AUTOSAR XML (schema 4-0-3)
package /ComponentTypes
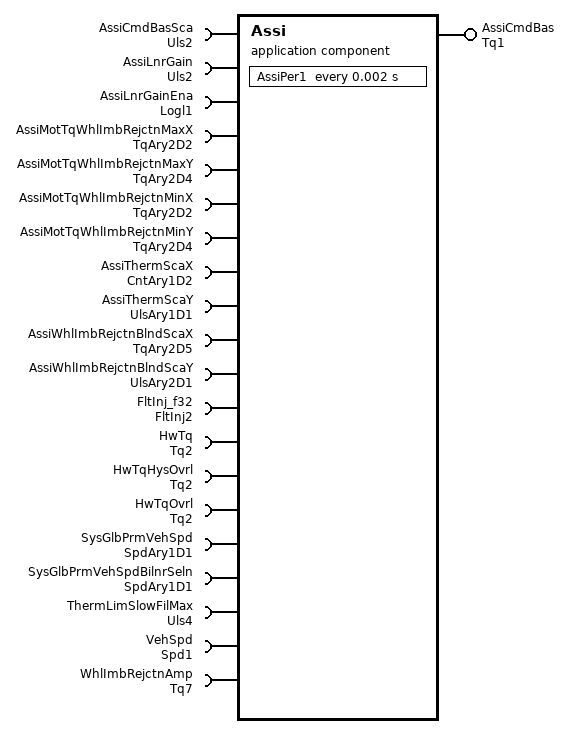
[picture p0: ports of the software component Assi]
  application sw component type Assi
    provide port AssiCmdBas: nonqueued-sender-com-spec{data-element=Val, init-value=0}, provided-interface=Tq1
    20 x require port:
      AssiCmdBasSca: nonqueued-receiver-com-spec{data-element=Val, filter=data-filter-type=ALWAYS, init-value=1}, required-interface=Uls2
      AssiLnrGain: nonqueued-receiver-com-spec{data-element=Val, filter=data-filter-type=ALWAYS, init-value=1}, required-interface=Uls2
      AssiLnrGainEna: nonqueued-receiver-com-spec{data-element=Logl, filter=data-filter-type=ALWAYS, init-value=0}, required-interface=Logl1
      AssiMotTqWhlImbRejctnMaxX: parameter-require-com-spec{init-value=[[0, 0.1015625, 0.2070313, 0.2460938, 0.2890625, 0.3359375, 0.3828125, 0.4296875, 0.4804688, 0.5234375, 0.5703125, 0.6210938, 0.6640625, 0.7109375, 0.7578125, 0.8007813, 1, 1.453125, 4.765625, 10], [0, 0.1015625, 0.3046875, 0.3945313, 0.4804688, 0.578125, 0.6679688, 0.765625, 0.859375, 0.9492188, 1.042969, 1.132813, 1.230469, 1.324219, 1.414063, 1.7, 2.2, 2.808594, 6.34375, 10], [0, 0.1992188, 0.3125, 0.4414063, 0.5664063, 0.6875, 0.8007813, 0.9296875, 1.039063, 1.160156, 1.289063, 1.40625, 1.527344, 1.648438, 1.765625, 2.1, 2.8, 3.578125, 8.65625, 10], [0, 0.1992188, 0.3125, 0.4296875, 0.5703125, 0.6757813, 0.8007813, 0.9257813, 1.039063, 1.167969, 1.289063, 1.40625, 1.53125, 1.652344, 1.765625, 1.890625, 2.5, 3.582031, 3.699219, 10], [0, 0.1992188, 0.3125, 0.4335938, 0.5585938, 0.6914063, 0.8085938, 0.9296875, 1.042969, 1.171875, 1.289063, 1.402344, 1.53125, 1.648438, 1.769531, 1.886719, 2.5, 3.2, 3.699219, 10], [0, 0.1992188, 0.3085938, 0.4335938, 0.5429688, 0.6796875, 0.8046875, 0.921875, 1.042969, 1.171875, 1.304688, 1.429688, 1.546875, 1.671875, 1.796875, 1.929688, 2.5, 3.2, 3.796875, 10], [0, 0.1992188, 0.3125, 0.4140625, 0.5546875, 0.6835938, 0.8007813, 0.9335938, 1.054688, 1.171875, 1.296875, 1.429688, 1.554688, 1.675781, 1.804688, 1.929688, 2.5, 3.2, 3.796875, 10], [0, 0.1992188, 0.390625, 0.5078125, 0.6367188, 0.7578125, 0.8945313, 1.019531, 1.136719, 1.265625, 1.386719, 1.515625, 1.640625, 1.761719, 1.886719, 2.011719, 2.5, 3.2, 3.898438, 10], [0, 0.1992188, 0.390625, 0.5078125, 0.640625, 0.765625, 0.90625, 1.015625, 1.160156, 1.277344, 1.40625, 1.546875, 1.679688, 1.804688, 1.925781, 2.058594, 2.6, 3.2, 4, 10], [0, 0.1992188, 0.390625, 0.5078125, 0.640625, 0.765625, 0.90625, 1.015625, 1.160156, 1.277344, 1.40625, 1.546875, 1.679688, 1.804688, 1.925781, 2.058594, 2.6, 3.2, 4, 10], [0, 0.1992188, 0.390625, 0.5078125, 0.640625, 0.765625, 0.90625, 1.015625, 1.160156, 1.277344, 1.40625, 1.546875, 1.679688, 1.804688, 1.925781, 2.058594, 2.6, 3.2, 4, 10], [0, 0.1992188, 0.390625, 0.5078125, 0.640625, 0.765625, 0.90625, 1.015625, 1.160156, 1.277344, 1.40625, 1.546875, 1.679688, 1.804688, 1.925781, 2.058594, 2.6, 3.2, 4, 10]], parameter=Ary2D}, required-interface=TqAry2D2
      AssiMotTqWhlImbRejctnMaxY: parameter-require-com-spec{init-value=[[0, 0, 0.0234375, 0.03515625, 0.05078125, 0.0703125, 0.09375, 0.1210938, 0.1523438, 0.1835938, 0.21875, 0.2617188, 0.3007813, 0.3476563, 0.3984375, 0.4492188, 0.75, 1.527344, 8.742188, 8.742188], [0, 0, 0.03125, 0.05078125, 0.07421875, 0.1054688, 0.140625, 0.1835938, 0.2304688, 0.28125, 0.3398438, 0.4023438, 0.4726563, 0.546875, 0.625, 0.86, 1.5, 2.5, 8.742188, 8.742188], [0, 0, 0.015625, 0.0390625, 0.06640625, 0.09765625, 0.1328125, 0.1757813, 0.21875, 0.2695313, 0.328125, 0.3867188, 0.453125, 0.5234375, 0.5976563, 0.85, 1.48, 2.308594, 8.742188, 8.742188], [0, 0, 0.015625, 0.03515625, 0.0625, 0.0859375, 0.1171875, 0.1523438, 0.1875, 0.2304688, 0.2734375, 0.3203125, 0.3710938, 0.4257813, 0.4804688, 0.5429688, 1, 1.742188, 1.851563, 7.632813], [0, 0, 0.015625, 0.03515625, 0.05859375, 0.0859375, 0.1132813, 0.1445313, 0.1757813, 0.2148438, 0.2539063, 0.2929688, 0.3398438, 0.3867188, 0.4375, 0.4882813, 0.85, 1.29, 1.621094, 6.578125], [0, 0, 0.015625, 0.03515625, 0.0546875, 0.08203125, 0.109375, 0.1367188, 0.1679688, 0.203125, 0.2421875, 0.28125, 0.3203125, 0.3632813, 0.4101563, 0.4609375, 0.75, 1.13, 1.476563, 5.679688], [0, 0, 0.015625, 0.03125, 0.0546875, 0.078125, 0.1015625, 0.1289063, 0.15625, 0.1835938, 0.2148438, 0.25, 0.2851563, 0.3203125, 0.359375, 0.3984375, 0.64, 0.94, 1.199219, 4.453125], [0, 0, 0.0234375, 0.0390625, 0.05859375, 0.078125, 0.1015625, 0.125, 0.1484375, 0.1757813, 0.203125, 0.234375, 0.265625, 0.296875, 0.3320313, 0.3671875, 0.55, 0.84, 1.105469, 4.039063], [0, 0, 0.0234375, 0.0390625, 0.05859375, 0.078125, 0.1015625, 0.1210937, 0.1484375, 0.171875, 0.1992187, 0.2304687, 0.2617187, 0.2929687, 0.3242187, 0.359375, 0.5, 0.75, 1.054687, 3.675781], [0, 0, 0.0234375, 0.0390625, 0.05859375, 0.078125, 0.1015625, 0.1210937, 0.1484375, 0.171875, 0.1992187, 0.2304687, 0.2617187, 0.2929687, 0.3242187, 0.359375, 0.5, 0.75, 1.054687, 3.675781], [0, 0, 0.0234375, 0.0390625, 0.05859375, 0.078125, 0.1015625, 0.1210937, 0.1484375, 0.171875, 0.1992187, 0.2304687, 0.2617187, 0.2929687, 0.3242187, 0.359375, 0.5, 0.75, 1.054687, 3.675781], [0, 0, 0.0234375, 0.0390625, 0.05859375, 0.078125, 0.1015625, 0.1210937, 0.1484375, 0.171875, 0.1992187, 0.2304687, 0.2617187, 0.2929687, 0.3242187, 0.359375, 0.5, 0.75, 1.054687, 3.675781]], parameter=Ary2D}, required-interface=TqAry2D4
      AssiMotTqWhlImbRejctnMinX: parameter-require-com-spec{init-value=[[0, 0.1015625, 0.2070313, 0.2460938, 0.2890625, 0.3359375, 0.3828125, 0.4296875, 0.4804688, 0.5234375, 0.5703125, 0.6210938, 0.6640625, 0.7109375, 0.7578125, 0.8007813, 1, 1.453125, 4.765625, 10], [0, 0.1015625, 0.3046875, 0.3945313, 0.4804688, 0.578125, 0.6679688, 0.765625, 0.859375, 0.9492188, 1.042969, 1.132813, 1.230469, 1.324219, 1.414063, 1.7, 2.2, 2.808594, 6.34375, 10], [0, 0.1992188, 0.3125, 0.4414063, 0.5664063, 0.6875, 0.8007813, 0.9296875, 1.039063, 1.160156, 1.289063, 1.40625, 1.527344, 1.648438, 1.765625, 2.1, 2.8, 3.578125, 8.65625, 10], [0, 0.1992188, 0.3125, 0.4296875, 0.5703125, 0.6757813, 0.8007813, 0.9257813, 1.039063, 1.167969, 1.289063, 1.40625, 1.53125, 1.652344, 1.765625, 1.890625, 2.5, 3.582031, 3.699219, 10], [0, 0.1992188, 0.3125, 0.4335938, 0.5585938, 0.6914063, 0.8085938, 0.9296875, 1.042969, 1.171875, 1.289063, 1.402344, 1.53125, 1.648438, 1.769531, 1.886719, 2.5, 3.2, 3.699219, 10], [0, 0.1992188, 0.3085938, 0.4335938, 0.5429688, 0.6796875, 0.8046875, 0.921875, 1.042969, 1.171875, 1.304688, 1.429688, 1.546875, 1.671875, 1.796875, 1.929688, 2.5, 3.2, 3.796875, 10], [0, 0.1992188, 0.3125, 0.4140625, 0.5546875, 0.6835938, 0.8007813, 0.9335938, 1.054688, 1.171875, 1.296875, 1.429688, 1.554688, 1.675781, 1.804688, 1.929688, 2.5, 3.2, 3.796875, 10], [0, 0.1992188, 0.390625, 0.5078125, 0.6367188, 0.7578125, 0.8945313, 1.019531, 1.136719, 1.265625, 1.386719, 1.515625, 1.640625, 1.761719, 1.886719, 2.011719, 2.5, 3.2, 3.898438, 10], [0, 0.1992188, 0.390625, 0.5078125, 0.640625, 0.765625, 0.90625, 1.015625, 1.160156, 1.277344, 1.40625, 1.546875, 1.679688, 1.804688, 1.925781, 2.058594, 2.6, 3.2, 4, 10], [0, 0.1992188, 0.390625, 0.5078125, 0.640625, 0.765625, 0.90625, 1.015625, 1.160156, 1.277344, 1.40625, 1.546875, 1.679688, 1.804688, 1.925781, 2.058594, 2.6, 3.2, 4, 10], [0, 0.1992188, 0.390625, 0.5078125, 0.640625, 0.765625, 0.90625, 1.015625, 1.160156, 1.277344, 1.40625, 1.546875, 1.679688, 1.804688, 1.925781, 2.058594, 2.6, 3.2, 4, 10], [0, 0.1992188, 0.390625, 0.5078125, 0.640625, 0.765625, 0.90625, 1.015625, 1.160156, 1.277344, 1.40625, 1.546875, 1.679688, 1.804688, 1.925781, 2.058594, 2.6, 3.2, 4, 10]], parameter=Ary2D}, required-interface=TqAry2D2
      AssiMotTqWhlImbRejctnMinY: parameter-require-com-spec{init-value=[[0, 0, 0.0234375, 0.03515625, 0.05078125, 0.0703125, 0.09375, 0.1210938, 0.1523438, 0.1835938, 0.21875, 0.2617188, 0.3007813, 0.3476563, 0.3984375, 0.4492188, 0.75, 1.527344, 8.742188, 8.742188], [0, 0, 0.03125, 0.05078125, 0.07421875, 0.1054688, 0.140625, 0.1835938, 0.2304688, 0.28125, 0.3398438, 0.4023438, 0.4726563, 0.546875, 0.625, 0.86, 1.5, 2.5, 8.742188, 8.742188], [0, 0, 0.015625, 0.0390625, 0.06640625, 0.09765625, 0.1328125, 0.1757813, 0.21875, 0.2695313, 0.328125, 0.3867188, 0.453125, 0.5234375, 0.5976563, 0.85, 1.48, 2.308594, 8.742188, 8.742188], [0, 0, 0.015625, 0.03515625, 0.0625, 0.0859375, 0.1171875, 0.1523438, 0.1875, 0.2304688, 0.2734375, 0.3203125, 0.3710938, 0.4257813, 0.4804688, 0.5429688, 1, 1.742188, 1.851563, 7.632813], [0, 0, 0.015625, 0.03515625, 0.05859375, 0.0859375, 0.1132813, 0.1445313, 0.1757813, 0.2148438, 0.2539063, 0.2929688, 0.3398438, 0.3867188, 0.4375, 0.4882813, 0.85, 1.29, 1.621094, 6.578125], [0, 0, 0.015625, 0.03515625, 0.0546875, 0.08203125, 0.109375, 0.1367188, 0.1679688, 0.203125, 0.2421875, 0.28125, 0.3203125, 0.3632813, 0.4101563, 0.4609375, 0.75, 1.13, 1.476563, 5.679688], [0, 0, 0.015625, 0.03125, 0.0546875, 0.078125, 0.1015625, 0.1289063, 0.15625, 0.1835938, 0.2148438, 0.25, 0.2851563, 0.3203125, 0.359375, 0.3984375, 0.64, 0.94, 1.199219, 4.453125], [0, 0, 0.0234375, 0.0390625, 0.05859375, 0.078125, 0.1015625, 0.125, 0.1484375, 0.1757813, 0.203125, 0.234375, 0.265625, 0.296875, 0.3320313, 0.3671875, 0.55, 0.84, 1.105469, 4.039063], [0, 0, 0.0234375, 0.0390625, 0.05859375, 0.078125, 0.1015625, 0.1210937, 0.1484375, 0.171875, 0.1992187, 0.2304687, 0.2617187, 0.2929687, 0.3242187, 0.359375, 0.5, 0.75, 1.054687, 3.675781], [0, 0, 0.0234375, 0.0390625, 0.05859375, 0.078125, 0.1015625, 0.1210937, 0.1484375, 0.171875, 0.1992187, 0.2304687, 0.2617187, 0.2929687, 0.3242187, 0.359375, 0.5, 0.75, 1.054687, 3.675781], [0, 0, 0.0234375, 0.0390625, 0.05859375, 0.078125, 0.1015625, 0.1210937, 0.1484375, 0.171875, 0.1992187, 0.2304687, 0.2617187, 0.2929687, 0.3242187, 0.359375, 0.5, 0.75, 1.054687, 3.675781], [0, 0, 0.0234375, 0.0390625, 0.05859375, 0.078125, 0.1015625, 0.1210937, 0.1484375, 0.171875, 0.1992187, 0.2304687, 0.2617187, 0.2929687, 0.3242187, 0.359375, 0.5, 0.75, 1.054687, 3.675781]], parameter=Ary2D}, required-interface=TqAry2D4
      AssiThermScaX: parameter-require-com-spec{init-value=[75, 100], parameter=Ary1D}, required-interface=CntAry1D2
      AssiThermScaY: parameter-require-com-spec{init-value=[1, 0.8], parameter=Ary1D}, required-interface=UlsAry1D1
      AssiWhlImbRejctnBlndScaX: parameter-require-com-spec{init-value=12 x [0, 0.25, 0.5, 0.75, 1.1], parameter=Ary2D}, required-interface=TqAry2D5
      AssiWhlImbRejctnBlndScaY: parameter-require-com-spec{init-value=12 x [0, 0, 0.5, 0.9, 1], parameter=Ary2D}, required-interface=UlsAry2D1
      FltInj_f32: required-interface=FltInj2
      HwTq: nonqueued-receiver-com-spec{data-element=Val, filter=data-filter-type=ALWAYS, init-value=0}, required-interface=Tq2
      HwTqHysOvrl: nonqueued-receiver-com-spec{data-element=Val, filter=data-filter-type=ALWAYS, init-value=0}, required-interface=Tq2
      HwTqOvrl: nonqueued-receiver-com-spec{data-element=Val, filter=data-filter-type=ALWAYS, init-value=0}, required-interface=Tq2
      SysGlbPrmVehSpd: parameter-require-com-spec{init-value=12 x 0, parameter=Ary1D}, required-interface=SpdAry1D1
      SysGlbPrmVehSpdBilnrSeln: parameter-require-com-spec{init-value=[0, 640, 1920, 3840, 7680, 10240, 12800, 15360, 19200, 23040, 25600, 28160], parameter=Ary1D}, required-interface=SpdAry1D1
      ThermLimSlowFilMax: nonqueued-receiver-com-spec{data-element=Val, filter=data-filter-type=ALWAYS, init-value=0}, required-interface=Uls4
      VehSpd: nonqueued-receiver-com-spec{data-element=Val, filter=data-filter-type=ALWAYS, init-value=0}, required-interface=Spd1
      WhlImbRejctnAmp: nonqueued-receiver-com-spec{data-element=Val, filter=data-filter-type=ALWAYS, init-value=0}, required-interface=Tq7
    behavior Assi_InternalBehavior: data-type-mapping=Nexteer
      ar-typed-per-instance-memorys:
        data dAssiThermAssiSca: sw-calibration-access=READ-ONLY, type=Uls2
        data dAssiWhlImbRejctnBlnd: sw-calibration-access=READ-ONLY, type=Uls2
      timing event TMT_AssiPer1: start-on-event=AssiPer1, period=0.002
      runnable AssiPer1
        data-receive-point-by-arguments:
          9 x access:
            REC_AssiCmdBasSca_Val: accessed-variable=AssiCmdBasSca.Val
            REC_AssiLnrGain_Val: accessed-variable=AssiLnrGain.Val
            REC_AssiLnrGainEn_Logl: accessed-variable=AssiLnrGainEna.Logl
            REC_HwTq_Val: accessed-variable=HwTq.Val
            REC_HwTqHysOvrl_Val: accessed-variable=HwTqHysOvrl.Val
            REC_HwTqOvrl_Val: accessed-variable=HwTqOvrl.Val
            REC_ThermLimSlowFilMax_Val: accessed-variable=ThermLimSlowFilMax.Val
            REC_VehSpd_Val_1: accessed-variable=VehSpd.Val
            REC_WhlImbRejctnAmp_Val_1: accessed-variable=WhlImbRejctnAmp.Val
        data-send-points:
          access SEND_AssiCmdBas_Val: accessed-variable=AssiCmdBas.Val
        sync call SC_FltInj_f32_Oper_1: operation=FltInj_f32.Oper, timeout=0
  swc implementation Assi_Implementation: behavior=Assi_InternalBehavior
    code-descriptors:
      code Default: artifact-descriptors=autosar-engineering-object={short-label=Default, category=SWSRC}
